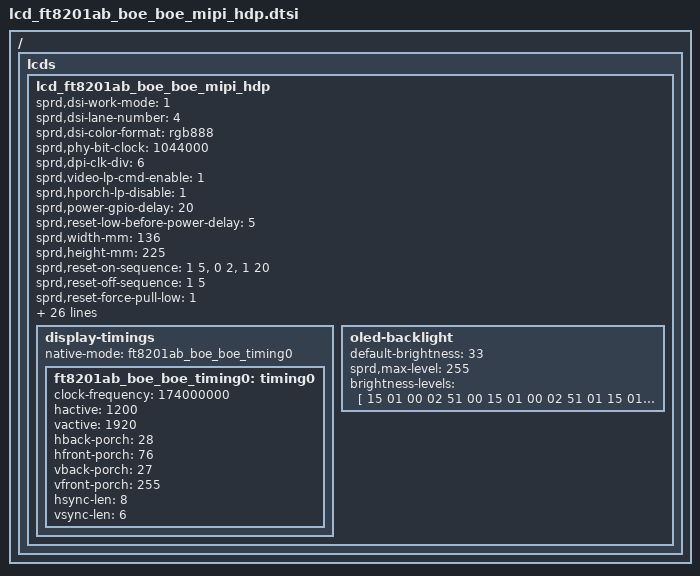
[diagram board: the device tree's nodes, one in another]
/**
*Name：<lcd_ft8201ab_boe_boe_mipi_hdp>
*Author：<huangzhongjie>
*Date：<2021/11/17>
*Purpose：<TAB A8 Focal LCD bring up>
*/
/ {
    fragment {
        target-path = "/";
        __overlay__ {
            lcds {
                lcd_ft8201ab_boe_boe_mipi_hdp: lcd_ft8201ab_boe_boe_mipi_hdp {

                    sprd,dsi-work-mode = <1>; /* video burst mode*/
                    sprd,dsi-lane-number = <4>;
                    sprd,dsi-color-format = "rgb888";

                    sprd,phy-bit-clock = <1044000>;    /* kbps */
                    sprd,dpi-clk-div = <6>;
                    sprd,video-lp-cmd-enable = <1>;
                    sprd,hporch-lp-disable = <1>;
                    sprd,power-gpio-delay = <20>;/* ms */
                    sprd,reset-low-before-power-delay = <5>;

                    sprd,width-mm = <136>;
                    sprd,height-mm = <225>;

                    sprd,reset-on-sequence = <1 5>, <0 2>, <1 20>;
                    sprd,reset-off-sequence = <1 5>;
                    sprd,reset-force-pull-low = <1>;
                    sprd,reset-delay-vspn-ms = <5>;
                    sprd,power-vsn-on-delay = <8>;

                    sprd,esd-check-enable = <1>;
                    sprd,esd-check-mode = <0>;
                    sprd,esd-check-double-reg-mode = <1>;
                    sprd,esd-check-reg-count = <2>;
                    sprd,esd-check-register = [0A 0E];
                    sprd,esd-check-value-len = <1 1>;
                    sprd,esd-check-value = [9C 80];
                    sprd,esd-check-period = <2000>;

                    sprd,initial-command = [
                        39 00 00 02 00 00
                        39 00 00 04 FF 82 01 01
                        39 00 00 02 00 80
                        39 00 00 03 FF 82 01
                        39 00 00 02 00 93
                        39 00 00 02 C5 84
                        39 00 00 02 00 97
                        39 00 00 02 C5 84
                        39 00 00 02 00 9E
                        39 00 00 02 C5 0A
                        39 00 00 02 00 9A
                        39 00 00 02 C5 C3
                        39 00 00 02 00 9C
                        39 00 00 02 C5 C3
                        39 00 00 02 00 B6
                        39 00 00 03 C5 75 75
                        39 00 00 02 00 B8
                        39 00 00 03 C5 39 39
                        39 00 00 02 00 A0
                        39 00 00 02 A5 04
                        39 00 00 02 00 00
                        39 00 00 03 D8 C8 C8
                        39 00 00 02 00 82
                        39 00 00 02 C5 95
                        39 00 00 02 00 83
                        39 00 00 02 C5 07
                        39 00 00 02 00 94
                        39 00 00 02 C5 46
                        39 00 00 02 00 98
                        39 00 00 02 C5 64
                        39 00 00 02 00 9B
                        39 00 00 02 C5 65
                        39 00 00 02 00 9D
                        39 00 00 02 C5 65
                        39 00 00 02 00 E6
                        39 00 00 02 C0 50
                        39 00 00 02 00 A7
                        39 00 00 02 F3 20
                        39 00 00 02 00 00
                        39 00 00 11 E1 04 0D 20 33 3E 4A 5C 6A 6C 7A 7C 92 70 5D 5E 53
                        39 00 00 02 00 10
                        39 00 00 09 E1 4C 41 32 2A 22 13 05 02
                        39 00 00 02 00 00
                        39 00 00 11 E2 04 0D 20 33 3E 4A 5C 6A 6C 7A 7C 92 70 5D 5E 53
                        39 00 00 02 00 10
                        39 00 00 09 E2 4C 41 32 2A 22 13 05 02
                        39 00 00 02 00 80
                        39 00 00 02 A4 8C
                        39 00 00 02 00 A0
                        39 00 00 02 F3 10
                        39 00 00 02 00 A1
                        39 00 00 03 B3 04 B0
                        39 00 00 02 00 A3
                        39 00 00 03 B3 07 80
                        39 00 00 02 00 A5
                        39 00 00 03 B3 80 13
                        39 00 00 02 00 D0
                        39 00 00 02 C1 B0
                        39 00 00 02 00 80
                        39 00 00 08 CB 33 33 00 33 30 33 30
                        39 00 00 02 00 87
                        39 00 00 02 CB 33
                        39 00 00 02 00 88
                        39 00 00 09 CB 33 33 33 33 33 30 33 33
                        39 00 00 02 00 90
                        39 00 00 08 CB 30 33 33 33 30 30 33
                        39 00 00 02 00 97
                        39 00 00 02 CB 33
                        39 00 00 02 00 98
                        39 00 00 09 CB 04 04 04 04 04 04 04 00
                        39 00 00 02 00 A0
                        39 00 00 09 CB 04 04 04 04 04 04 04 04
                        39 00 00 02 00 A8
                        39 00 00 09 CB 04 04 04 04 04 04 04 04
                        39 00 00 02 00 B0
                        39 00 00 08 CB 00 00 00 00 00 00 00
                        39 00 00 02 00 B7
                        39 00 00 02 CB 00
                        39 00 00 02 00 B8
                        39 00 00 09 CB 00 00 00 00 00 00 00 00
                        39 00 00 02 00 C0
                        39 00 00 08 CB 00 00 00 00 00 00 00
                        39 00 00 02 00 C7
                        39 00 00 02 CB 00
                        39 00 00 02 00 80
                        39 00 00 09 CC 29 29 2A 2A 0A 0A 06 06
                        39 00 00 02 00 88
                        39 00 00 09 CC 0F 0F 35 35 34 34 16 16
                        39 00 00 02 00 90
                        39 00 00 07 CC 14 14 1A 1A 18 18
                        39 00 00 02 00 80
                        39 00 00 09 CD 29 29 2A 2A 09 09 05 05
                        39 00 00 02 00 88
                        39 00 00 09 CD 0F 0F 35 35 34 34 15 15
                        39 00 00 02 00 90
                        39 00 00 07 CD 13 13 19 19 17 17
                        39 00 00 02 00 A0
                        39 00 00 09 CC 29 29 2A 2A 09 09 05 05
                        39 00 00 02 00 A8
                        39 00 00 09 CC 0F 0F 35 35 34 34 17 17
                        39 00 00 02 00 B0
                        39 00 00 07 CC 19 19 13 13 15 15
                        39 00 00 02 00 A0
                        39 00 00 09 CD 29 29 2A 2A 0A 0A 06 06
                        39 00 00 02 00 A8
                        39 00 00 09 CD 0F 0F 35 35 34 34 18 18
                        39 00 00 02 00 B0
                        39 00 00 07 CD 1A 1A 14 14 16 16
                        39 00 00 02 00 81
                        39 00 00 02 C2 40
                        39 00 00 02 00 88
                        39 00 00 05 C2 8A 04 7C 9D
                        39 00 00 02 00 8C
                        39 00 00 05 C2 89 04 7C 9D
                        39 00 00 02 00 98
                        39 00 00 05 C2 90 24 7C 9D
                        39 00 00 02 00 9C
                        39 00 00 05 C2 8F 24 7C 9D
                        39 00 00 02 00 B8
                        39 00 00 05 C2 11 04 7C 9D
                        39 00 00 02 00 BC
                        39 00 00 05 C2 12 04 7C 9D
                        39 00 00 02 00 80
                        39 00 00 09 C3 88 0D 24 89 AA 00 02 07
                        39 00 00 02 00 88
                        39 00 00 09 C3 87 0E 24 89 AA 00 02 07
                        39 00 00 02 00 90
                        39 00 00 09 C3 86 0F 24 89 AA 00 02 07
                        39 00 00 02 00 98
                        39 00 00 09 C3 85 10 24 89 AA 00 02 07
                        39 00 00 02 00 C0
                        39 00 00 09 CD 84 09 24 89 AA 00 02 07
                        39 00 00 02 00 C8
                        39 00 00 09 CD 83 0A 24 89 AA 00 02 07
                        39 00 00 02 00 D0
                        39 00 00 09 CD 82 0B 24 89 AA 00 02 07
                        39 00 00 02 00 D8
                        39 00 00 09 CD 81 0C 24 89 AA 00 02 07
                        39 00 00 02 00 F0
                        39 00 00 06 CC 79 97 00 00 00
                        39 00 00 02 00 FD
                        39 00 00 02 CB 82
                        39 00 00 02 00 80
                        39 00 00 07 C0 00 96 01 09 00 17
                        39 00 00 02 00 90
                        39 00 00 07 C0 00 96 01 09 00 17
                        39 00 00 02 00 A0
                        39 00 00 07 C0 01 27 01 10 00 10
                        39 00 00 02 00 B0
                        39 00 00 06 C0 00 96 01 09 17
                        39 00 00 02 00 A3
                        39 00 00 04 C1 22 22 04
                        39 00 00 02 00 80
                        39 00 00 02 CE 00
                        39 00 00 02 00 90
                        39 00 00 02 CE 00
                        39 00 00 02 00 D0
                        39 00 00 09 CE 01 00 18 01 01 00 EF 01
                        39 00 00 02 00 E0
                        39 00 00 02 CE 00
                        39 00 00 02 00 F0
                        39 00 00 02 CE 00
                        39 00 00 02 00 B0
                        39 00 00 05 CF 06 06 40 44
                        39 00 00 02 00 B5
                        39 00 00 05 CF 03 03 BC C0
                        39 00 00 02 00 C0
                        39 00 00 05 CF 07 07 58 5C
                        39 00 00 02 00 C5
                        39 00 00 05 CF 00 07 08 80
                        39 00 00 02 00 90
                        39 00 00 02 C4 88
                        39 00 00 02 00 92
                        39 00 00 02 C4 C0
                        39 00 00 02 00 C8
                        39 00 00 04 C3 00 00 00
                        39 00 00 02 00 C9
                        39 00 00 02 CE 00
                        39 00 00 02 1C 00
                        39 00 00 02 00 D6
                        39 00 00 02 C1 00
                        39 00 00 02 00 D5
                        39 00 00 02 C0 F0
                        39 00 00 02 00 A0
                        39 00 00 02 C1 E0
                        39 00 00 02 00 9F
                        39 00 00 02 C5 00
                        39 00 00 02 00 91
                        39 00 00 02 C5 4C
                        39 00 00 02 00 D7
                        39 00 00 02 CE 01
                        39 00 00 02 00 82
                        39 00 00 02 A5 01
                        39 00 00 02 00 8C
                        39 00 00 03 CF 40 40
                        39 00 00 02 00 9A
                        39 00 00 02 F5 35
                        39 00 00 02 00 A2
                        39 00 00 02 F5 1F
                        39 00 00 02 00 B2
                        39 00 00 02 C5 15
                        39 00 00 02 00 B5
                        39 00 00 02 C5 05
                        39 00 00 02 00 A4
                        39 00 00 02 F3 0B
                        39 00 00 02 00 00
                        39 00 00 02 FA 02
                        39 00 00 02 00 A8
                        39 00 00 02 C5 09
                        39 00 00 02 00 CB
                        39 00 00 02 C5 01
                        39 00 00 02 00 B6
                        39 00 00 03 C5 75 75
                        39 00 00 02 00 B8
                        39 00 00 03 C5 39 39
                        39 00 00 02 00 91
                        39 00 00 02 A5 00
                        39 00 00 02 00 B0
                        39 00 00 02 C5 00
                        39 00 00 02 00 B3
                        39 00 00 02 C5 00
                        39 00 00 02 00 A4
                        39 00 00 02 F3 0B
                        39 00 00 02 00 00
                        39 00 00 02 FA 5A
                        39 00 00 02 00 A4
                        39 00 00 02 F3 0B
                        39 00 00 02 00 00
                        39 00 00 02 FA 01
                        39 00 00 02 00 A8
                        39 00 00 02 C5 09
                        39 00 00 02 00 CB
                        39 00 00 02 C5 09
                        39 00 00 02 00 B6
                        39 00 00 03 C5 73 73
                        39 00 00 02 00 B8
                        39 00 00 03 C5 37 37
                        39 00 00 02 00 91
                        39 00 00 02 A5 40
                        39 00 00 02 00 B0
                        39 00 00 02 C5 41
                        39 00 00 02 00 B3
                        39 00 00 02 C5 41
                        39 00 00 02 00 A4
                        39 00 00 02 F3 0B
                        39 00 00 02 00 00
                        39 00 00 02 FA 5A
                        39 00 00 02 00 90
                        39 00 00 02 E9 10
                        39 00 00 02 00 B0
                        39 00 00 06 CA 00 00 04 00 06
                        39 00 00 02 00 00
                        39 00 00 04 FF 00 00 00
                        39 00 00 02 00 80
                        39 00 00 03 FF 00 00
                        39 00 00 03 51 00 00
                        39 00 00 02 53 2C
                        39 00 00 02 55 00
                        39 00 00 02 35 00
                        05 5A 00 01 11
                        05 14 00 01 29
                    ];

                    sprd,sleep-in-command = [
                        05 14 00 01 28
                        05 8C 00 01 10
                        39 00 00 02 00 00
                        39 05 00 05 F7 5A A5 95 27
                    ];

                    sprd,sleep-out-command = [
                        23 5A 00 23 11 00
                        23 14 00 23 29 00
                    ];

                    sprd,pwm-diming-off-command = [
                        39 00 00 02 53 24
                    ];

                    sprd,esd-check-enable-cmd = [
                        15 00 00 02 00 00
                        15 00 00 02 FF 82
                        15 00 00 02 FF 01
                        15 00 00 02 FF 01
                        15 00 00 02 00 80
                        15 00 00 02 FF 82
                        15 00 00 02 FF 01
                    ];

                    sprd,esd-check-read-master-cmd = [
                        15 00 00 02 00 88
                        15 00 00 02 B0 07
                        15 00 00 02 00 00
                        15 00 00 02 FA 02
                    ];

                    sprd,esd-check-read-salve-cmd = [
                        15 00 00 02 00 88
                        15 00 00 02 B0 07
                        15 00 00 02 00 00
                        15 00 00 02 FA 01
                    ];

                    sprd,esd-check-return-to-normal-cmd = [
                        15 00 00 02 00 00
                        15 00 00 02 FA 5A
                        15 00 00 02 00 88
                        15 00 00 02 B0 01
                    ];

                    display-timings {
                        native-mode = <&ft8201ab_boe_boe_timing0>;
                        ft8201ab_boe_boe_timing0: timing0 {
                        clock-frequency = <174000000>;
                            hactive = <1200>;
                            vactive = <1920>;
                            hback-porch = <28>;
                            hfront-porch = <76>;
                            vback-porch = <27>;
                            vfront-porch = <255>;
                            hsync-len = <8>;
                            vsync-len = <6>;

                        };
                    };

                    oled-backlight {
                        default-brightness = <33>;
                        sprd,max-level = <255>;

                        brightness-levels = [
                            15 01 00 02 51 00
                            15 01 00 02 51 01
                            15 01 00 02 51 02
                            15 01 00 02 51 03
                            15 01 00 02 51 04
                            15 01 00 02 51 05
                            15 01 00 02 51 06
                            15 01 00 02 51 07
                            15 01 00 02 51 08
                            15 01 00 02 51 09
                            15 01 00 02 51 0A
                            15 01 00 02 51 0B
                            15 01 00 02 51 0C
                            15 01 00 02 51 0D
                            15 01 00 02 51 0E
                            15 01 00 02 51 0F
                            15 01 00 02 51 10
                            15 01 00 02 51 11
                            15 01 00 02 51 12
                            15 01 00 02 51 13
                            15 01 00 02 51 14
                            15 01 00 02 51 15
                            15 01 00 02 51 16
                            15 01 00 02 51 17
                            15 01 00 02 51 18
                            15 01 00 02 51 19
                            15 01 00 02 51 1A
                            15 01 00 02 51 1B
                            15 01 00 02 51 1C
                            15 01 00 02 51 1D
                            15 01 00 02 51 1E
                            15 01 00 02 51 1F
                            15 01 00 02 51 20
                            15 01 00 02 51 21
                            15 01 00 02 51 22
                            15 01 00 02 51 23
                            15 01 00 02 51 24
                            15 01 00 02 51 25
                            15 01 00 02 51 26
                            15 01 00 02 51 27
                            15 01 00 02 51 28
                            15 01 00 02 51 29
                            15 01 00 02 51 2A
                            15 01 00 02 51 2B
                            15 01 00 02 51 2C
                            15 01 00 02 51 2D
                            15 01 00 02 51 2E
                            15 01 00 02 51 2F
                            15 01 00 02 51 30
                            15 01 00 02 51 31
                            15 01 00 02 51 32
                            15 01 00 02 51 33
                            15 01 00 02 51 34
                            15 01 00 02 51 35
                            15 01 00 02 51 36
                            15 01 00 02 51 37
                            15 01 00 02 51 38
                            15 01 00 02 51 39
                            15 01 00 02 51 3A
                            15 01 00 02 51 3B
                            15 01 00 02 51 3C
                            15 01 00 02 51 3D
                            15 01 00 02 51 3E
                            15 01 00 02 51 3F
                            15 01 00 02 51 40
                            15 01 00 02 51 41
                            15 01 00 02 51 42
                            15 01 00 02 51 43
                            15 01 00 02 51 44
                            15 01 00 02 51 45
                            15 01 00 02 51 46
                            15 01 00 02 51 47
                            15 01 00 02 51 48
                            15 01 00 02 51 49
                            15 01 00 02 51 4A
                            15 01 00 02 51 4B
                            15 01 00 02 51 4C
                            15 01 00 02 51 4D
                            15 01 00 02 51 4E
                            15 01 00 02 51 4F
                            15 01 00 02 51 50
                            15 01 00 02 51 51
                            15 01 00 02 51 52
                            15 01 00 02 51 53
                            15 01 00 02 51 54
                            15 01 00 02 51 55
                            15 01 00 02 51 56
                            15 01 00 02 51 57
                            15 01 00 02 51 58
                            15 01 00 02 51 59
                            15 01 00 02 51 5A
                            15 01 00 02 51 5B
                            15 01 00 02 51 5C
                            15 01 00 02 51 5D
                            15 01 00 02 51 5E
                            15 01 00 02 51 5F
                            15 01 00 02 51 60
                            15 01 00 02 51 61
                            15 01 00 02 51 62
                            15 01 00 02 51 63
                            15 01 00 02 51 64
                            15 01 00 02 51 65
                            15 01 00 02 51 66
                            15 01 00 02 51 67
                            15 01 00 02 51 68
                            15 01 00 02 51 69
                            15 01 00 02 51 6A
                            15 01 00 02 51 6B
                            15 01 00 02 51 6C
                            15 01 00 02 51 6D
                            15 01 00 02 51 6E
                            15 01 00 02 51 6F
                            15 01 00 02 51 70
                            15 01 00 02 51 71
                            15 01 00 02 51 72
                            15 01 00 02 51 73
                            15 01 00 02 51 74
                            15 01 00 02 51 75
                            15 01 00 02 51 76
                            15 01 00 02 51 77
                            15 01 00 02 51 78
                            15 01 00 02 51 79
                            15 01 00 02 51 7A
                            15 01 00 02 51 7B
                            15 01 00 02 51 7C
                            15 01 00 02 51 7D
                            15 01 00 02 51 7E
                            15 01 00 02 51 7F
                            15 01 00 02 51 80
                            15 01 00 02 51 81
                            15 01 00 02 51 82
                            15 01 00 02 51 83
                            15 01 00 02 51 84
                            15 01 00 02 51 85
                            15 01 00 02 51 86
                            15 01 00 02 51 87
                            15 01 00 02 51 88
                            15 01 00 02 51 89
                            15 01 00 02 51 8A
                            15 01 00 02 51 8B
                            15 01 00 02 51 8C
                            15 01 00 02 51 8D
                            15 01 00 02 51 8E
                            15 01 00 02 51 8F
                            15 01 00 02 51 90
                            15 01 00 02 51 91
                            15 01 00 02 51 92
                            15 01 00 02 51 93
                            15 01 00 02 51 94
                            15 01 00 02 51 95
                            15 01 00 02 51 96
                            15 01 00 02 51 97
                            15 01 00 02 51 98
                            15 01 00 02 51 99
                            15 01 00 02 51 9A
                            15 01 00 02 51 9B
                            15 01 00 02 51 9C
                            15 01 00 02 51 9D
                            15 01 00 02 51 9E
                            15 01 00 02 51 9F
                            15 01 00 02 51 A0
                            15 01 00 02 51 A1
                            15 01 00 02 51 A2
                            15 01 00 02 51 A3
                            15 01 00 02 51 A4
                            15 01 00 02 51 A5
                            15 01 00 02 51 A6
                            15 01 00 02 51 A7
                            15 01 00 02 51 A8
                            15 01 00 02 51 A9
                            15 01 00 02 51 AA
                            15 01 00 02 51 AB
                            15 01 00 02 51 AC
                            15 01 00 02 51 AD
                            15 01 00 02 51 AE
                            15 01 00 02 51 AF
                            15 01 00 02 51 B0
                            15 01 00 02 51 B1
                            15 01 00 02 51 B2
                            15 01 00 02 51 B3
                            15 01 00 02 51 B4
                            15 01 00 02 51 B5
                            15 01 00 02 51 B6
                            15 01 00 02 51 B7
                            15 01 00 02 51 B8
                            15 01 00 02 51 B9
                            15 01 00 02 51 BA
                            15 01 00 02 51 BB
                            15 01 00 02 51 BC
                            15 01 00 02 51 BD
                            15 01 00 02 51 BE
                            15 01 00 02 51 BF
                            15 01 00 02 51 C0
                            15 01 00 02 51 C1
                            15 01 00 02 51 C2
                            15 01 00 02 51 C3
                            15 01 00 02 51 C4
                            15 01 00 02 51 C5
                            15 01 00 02 51 C6
                            15 01 00 02 51 C7
                            15 01 00 02 51 C8
                            15 01 00 02 51 C9
                            15 01 00 02 51 CA
                            15 01 00 02 51 CB
                            15 01 00 02 51 CC
                            15 01 00 02 51 CD
                            15 01 00 02 51 CE
                            15 01 00 02 51 CF
                            15 01 00 02 51 D0
                            15 01 00 02 51 D1
                            15 01 00 02 51 D2
                            15 01 00 02 51 D3
                            15 01 00 02 51 D4
                            15 01 00 02 51 D5
                            15 01 00 02 51 D6
                            15 01 00 02 51 D7
                            15 01 00 02 51 D8
                            15 01 00 02 51 D9
                            15 01 00 02 51 DA
                            15 01 00 02 51 DB
                            15 01 00 02 51 DC
                            15 01 00 02 51 DD
                            15 01 00 02 51 DE
                            15 01 00 02 51 DF
                            15 01 00 02 51 E0
                            15 01 00 02 51 E1
                            15 01 00 02 51 E2
                            15 01 00 02 51 E3
                            15 01 00 02 51 E4
                            15 01 00 02 51 E5
                            15 01 00 02 51 E6
                            15 01 00 02 51 E7
                            15 01 00 02 51 E8
                            15 01 00 02 51 E9
                            15 01 00 02 51 EA
                            15 01 00 02 51 EB
                            15 01 00 02 51 EC
                            15 01 00 02 51 ED
                            15 01 00 02 51 EE
                            15 01 00 02 51 EF
                            15 01 00 02 51 F0
                            15 01 00 02 51 F1
                            15 01 00 02 51 F2
                            15 01 00 02 51 F3
                            15 01 00 02 51 F4
                            15 01 00 02 51 F5
                            15 01 00 02 51 F6
                            15 01 00 02 51 F7
                            15 01 00 02 51 F8
                            15 01 00 02 51 F9
                            15 01 00 02 51 FA
                            15 01 00 02 51 FB
                            15 01 00 02 51 FC
                            15 01 00 02 51 FD
                            15 01 00 02 51 FE
                            15 01 00 02 51 FF
                        ];
                    };
                };
            };
        };
    };
};
